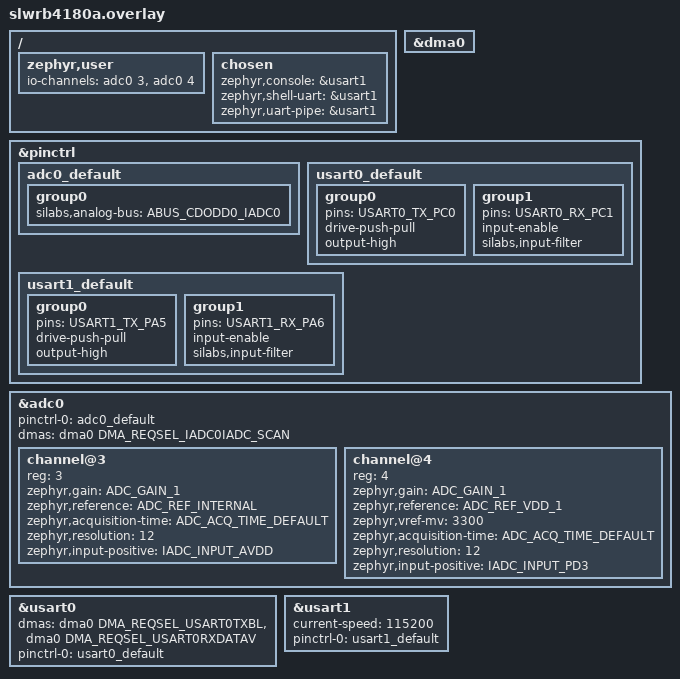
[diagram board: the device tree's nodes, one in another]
/*
 * Copyright (c) 2024 Silicon Laboratories, Inc.
 *
 * SPDX-License-Identifier: Apache-2.0
 */

&dma0 {
	status = "okay";
};

tst_dma0: &dma0 {};

#include <zephyr/dt-bindings/adc/silabs-adc.h>

/ {
	zephyr,user {
		io-channels = <&adc0 3>, <&adc0 4>;
	};
};

&pinctrl {
	adc0_default: adc0_default {
		group0 {
			silabs,analog-bus = <ABUS_CDODD0_IADC0>;
		};
	};
};

&adc0 {
	pinctrl-0 = <&adc0_default>;
	pinctrl-names = "default";
	dmas = <&dma0 DMA_REQSEL_IADC0IADC_SCAN>;
	#address-cells = <1>;
	#size-cells = <0>;
	status = "okay";
	channel@3 {
		reg = <3>;
		zephyr,gain = "ADC_GAIN_1";
		zephyr,reference = "ADC_REF_INTERNAL";
		zephyr,acquisition-time = <ADC_ACQ_TIME_DEFAULT>;
		zephyr,resolution = <12>;
		zephyr,input-positive = <IADC_INPUT_AVDD>;
	};
	channel@4 {
		reg = <4>;
		zephyr,gain = "ADC_GAIN_1";
		zephyr,reference = "ADC_REF_VDD_1";
		zephyr,vref-mv = <3300>;
		zephyr,acquisition-time = <ADC_ACQ_TIME_DEFAULT>;
		zephyr,resolution = <12>;
		zephyr,input-positive = <IADC_INPUT_PD3>;
	};
};

/ {
	chosen {
		zephyr,console = &usart1;
		zephyr,shell-uart = &usart1;
		zephyr,uart-pipe = &usart1;
	};
};

&pinctrl {
	usart0_default: usart0_default {
		group0 {
			pins = <USART0_TX_PC0>;
			drive-push-pull;
			output-high;
		};
		group1 {
			pins = <USART0_RX_PC1>;
			input-enable;
			silabs,input-filter;
		};
	};
	usart1_default: usart1_default {
		group0 {
			pins = <USART1_TX_PA5>;
			drive-push-pull;
			output-high;
		};
		group1 {
			pins = <USART1_RX_PA6>;
			input-enable;
			silabs,input-filter;
		};
	};
};

dut: &usart0 {
	dmas = <&dma0 DMA_REQSEL_USART0TXBL>,
	       <&dma0 DMA_REQSEL_USART0RXDATAV>;
	dma-names = "tx", "rx";
	pinctrl-0 = <&usart0_default>;
	pinctrl-names = "default";
};

&usart1 {
	current-speed = <115200>;
	pinctrl-0 = <&usart1_default>;
	pinctrl-names = "default";
	status = "okay";
};
